# CC2753 register map
File version: 1.0
CPU: CM0+ r0p4, little endian, no MPU, no FPU, VTOR, 3 interrupt priority bits
Registers are 32-bit, read-write, reset 0x0 unless marked. A register's access mark holds for its fields unless they carry their own. Offsets are from the block's base; [hi:lo] are bit positions; {n}, {i} and the like mark numbered series; 'fields as' and 'values as' point back to an identical list.

## CKMD (part 2 of 2) — Clock Controller
Base 0x40001000
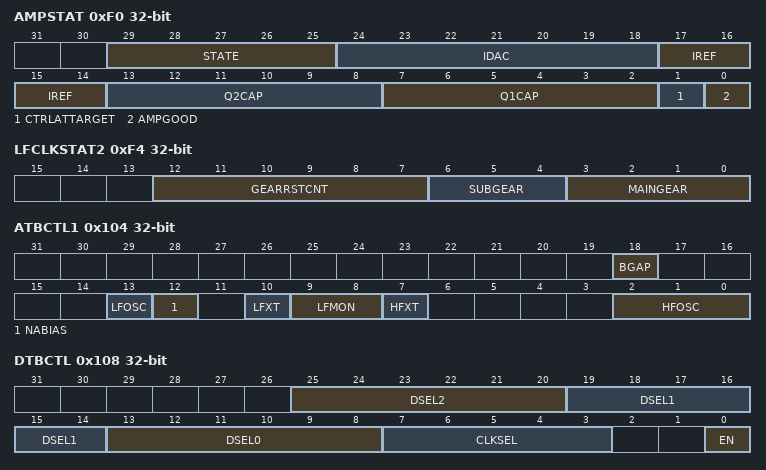
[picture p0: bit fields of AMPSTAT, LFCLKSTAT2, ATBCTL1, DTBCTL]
0xF0 AMPSTAT ro — HFXT Amplitude Compensation Status
  [29:25] STATE — Current AMPCOMP FSM state.
    15=SHUTDN1; 14=TXCOMODE; 13=SHUTDN0; 12=SETTLED; 10=TCXOWAIT; 7=RAMP1; 6=RAMP0; 5=UPDATEDN; 4=UPDATEUP; 3=INJECT; 2=INJWAIT; 1=LDOSTART; 0=IDLE
  [24:18] IDAC — Current IDAC control value.
  [17:14] IREF — Current IREF control value.
  [13:8] Q2CAP — Current Q2CAP control value.
  [7:2] Q1CAP — Current Q1CAP control value.
  [1] CTRLATTARGET — HFXT control values match target values. This applies to IREF, Q1CAP, Q2CAP values.
  [0] AMPGOOD — HFXT amplitude good
0xF4 LFCLKSTAT2 ro — Low-frequency clock status-2
  [12:7] GEARRSTCNT — Indicates the number of gear restarts. The counter is automatically cleared on the following events:- 1. Standby entry 2. Clearing RIS.LFGEARRSTRTLIM 3. Writing 0 to LFINCCTL2.GEARRSTRTLIM
  [6:4] SUBGEAR — The value of sub gear in LF filter. It counts from 0 to 7.
  [3:0] MAINGEAR — The value of main gear in LF filter. The main gear increments when the sub gear crosses 7.
0x100 ATBCTL0 — Analog test bus controls. This register is used in combination with ATBCTL1. For complete overview see [Block diagram] (https://confluence.itg.ti.com/display/LPRF/Hugin+-+AUXANATOP3+ATB+configuration#HuginAUXANATOP3ATBconfiguration-ATBdescription ) Ony the configurations mentioned in enumerations must be used. Other combinations might result in physical damage on the device. A write of 0x00 is recommended before changing to another connection configuration. All fields within this register are locked using the global-lock within SYS0.
  [23:0] SEL — Testmux selection ALWAYS write this signal to 0 (OFF), before selecting another configuration! Not following this might result in device damage.
    0x800000=LFDLYOPGATE (Gate output of LF delay block when set to 1); 0x400000=LFDLYINPGATE (Gate input clock to LF delay block when set to 1); 0x90000=BAWTESTCLK (BAW test clock connected to vr_atb_ckmanatop_clk); 0x50000=LFOSCTESTCLK (ull_ckm_lfosc_testclk connected to vr_atb_ckmanatop_clk); 0x30000=HFXTTESTCLK (ull_ckm_hfxt_testclk connected to vr_atb_ckmanatop_clk); 0x10000=HFOSCTESTCLK (ull_ckm_hfosc_testclk connected to vr_atb_ckmanatop_clk); 0x800=EXTCLKBUFPEAKDET (vr_atb_ckmextclkbuff_pd_mux_to_adc_o connected to vr_atb_ckmanatop_ana); 0x400=LFMONVTEST (vr_atb_lfmonitor_vtest connected to vr_atb_ckmanatop_ana); 0x200=BAWTEMP (BAW TEMPSENSE test output connected to vr_atb_ckmanatop_ana); 0x100=HFOSCOUT (vr_atb_hfosc_out connected to vr_atb_ckmanatop_ana); 128=NABIASITEST (vr_atb_nabias_itest_250n_dn connected to vr_atb_ckmanatop_ana); 64=ADCDACOUT (vr_atb_hfxtadc_dacout connected to vr_atb_ckmanatop_ana); 32=ADCCOMPIN (vr_atb_hfxtadc_compin connected to vr_atb_ckmanatop_ana); 16=ADCCOMPOUT (vr_atb_hfxtadc_compout connected to vr_atb_ckmanatop_ana); 8=BAWVBUF (BAW voltage buffer test output connected to vr_atb_ckmanatop_ana); 4=BAWCORE (BAW core test output connected to vr_atb_ckmanatop_ana); 2=VDDCKM (vr_atb_ckmldo_vddckm connected to vr_atb_ckmanatop_ana); 1=HFXTANA (vr_atb_hfxt_ana connected to vr_atb_ckmanatop_ana); 0=OFF (No signal connected to ATB. All outputs high impedance)
0x104 ATBCTL1 — Analog test bus controls This register is used in combination withATBCTL0. For complete overview see [Block diagram] (https://confluence.itg.ti.com/display/LPRF/Hugin+-+AUXANATOP3+ATB+configuration#HuginAUXANATOP3ATBconfiguration-ATBdescription ) All fields within this register are locked using the global-lock within SYS0.
  [18] BGAP — Control HFOSC voltage buffer test output signals Cannot be used if HFOSC is set to VREF or VINT. A write of 0x00 is recommended before changing to another connection configuration.
    1=VBUF (Enables HFOSC voltage buffer connection to ATB0.); 0=OFF (No output signal selected. Output is floating.)
  [13] LFOSC — Control LFOSC test output signals
    1=TESTCLK (LFOSC test clock); 0=OFF (No output signal selected. Output clock is grounded.)
  [12] NABIAS — Enable NABIAS test mode.
    1=ITEST (NABIAS Itest Enable.); 0=OFF (No output signal selected. Output signal is floating.)
  [10] LFXT — Control LFXT test output signals
    1=TESTCLK (LFXT test clock); 0=OFF (No output signal selected)
  [9:8] LFMON — Control LFMON test output signals
    3=TEST3 (LF monitor status signal); 2=TEST2 (Test signal 2 / in phase with inverted clock signal); 1=TEST1 (Test signal 1 / in phase with LF clock); 0=OFF (No output signal selected. Output signal is floating.)
  [7] HFXT — Enable HFXT test mode.
    1=IREF (HFXT CORE Iref connected to ATEST Bus and enable HFXT/BAW clock to test clock mux. Do not use this test feature if HFXT and BAW are on at the same time, this will damage the device); 0=OFF (No output signal selected. IREF output is floating, clocks are grounded.)
  [2:0] HFOSC — Control HFOSC test output signals VREF and VINT cannot be set at the same time, this might result in physical damage on the device. They also can't be used if BGAP is 0x1. TESTCLK can be used independantly all these enumerations. A write of 0x00 is recommended before changing to another connection configuration.
    4=TESTCLK (HFOSC test clock on ATB); 2=VINT (Enables internally generated supply connection to ATB); 1=VREF (Enables reference voltage connection to ATB); 0=OFF (No output signal selected. Voltage output is floating, clock output is grounded.)
0x108 DTBCTL — Digital test bus mux control
  [25:20] DSEL2 — Select data to output on DTB[15:11]
  [19:14] DSEL1 — Select data to output on DTB[10:6]
  [13:8] DSEL0 — Select data to output on DTB[5:1]
  [7:3] CLKSEL — Select clock to output on DTB[0]
  [0] EN — Enable DTB output
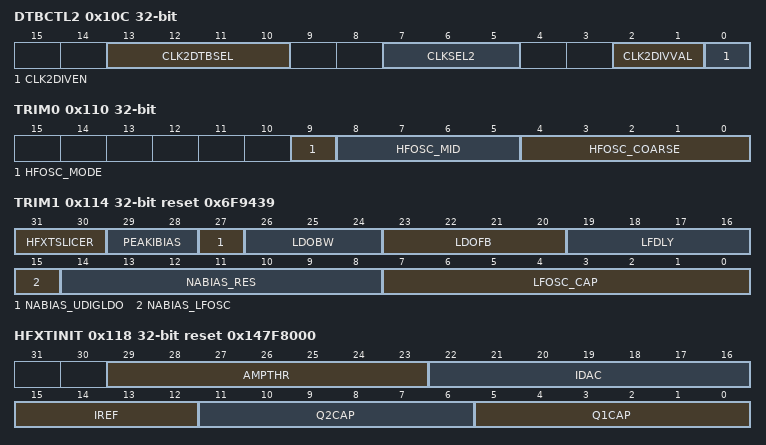
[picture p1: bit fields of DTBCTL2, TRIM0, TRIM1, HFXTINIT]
0x10C DTBCTL2 — Digital test bus mux control
  [13:10] CLK2DTBSEL — Select a DTB other than DTB0 to route the clock. Value of 0 indicates that clock 2 won't be sent to DTB.
  [7:5] CLKSEL2 — Select the clock that needs to be routed to a DTB other than DTB0
  [2:1] CLK2DIVVAL — These bits are used to configure the divider value.
    3=DIVBY16 (Divide by 16); 2=DIVBY8 (Divide by 8); 1=DIVBY4 (Divide by 4); 0=DIVBY2 (Divide by 2)
  [0] CLK2DIVEN — Enable divider on second clock path
    1=EN (Enable); 0=DIS (Disable)
0x110 TRIM0 — Production Trim Register 0 Note: This register contains the HFOSC coarse trims. Changing it might result in frequency overshoots. To prevent these from reaching the system, the clock is gated off for some periods after writing this register.
  [9] HFOSC_MODE — HFOSC mode trim. This field is locked using the global-lock within SYS0.
  [8:5] HFOSC_MID — HFOSC mid trim Binary coded. Default is 0x0. Never set to max code without a trim sweep. This field is locked using the global-lock within SYS0.
  [4:0] HFOSC_COARSE — HFOSC coarse trim. Binary coded. Default is 0x0. Never set to max code without a trim sweep. This field is locked using the global-lock within SYS0.
0x114 TRIM1 reset 0x6F9439 — Production Trim Register 1
  [31:30] HFXTSLICER — Bias current trim for HFXT slicer. 0x0: Minimum current 0x3: Maximum Current
  [29:28] PEAKIBIAS — IBIAS value for the HFXT peak detector 0x0: 16uA 0x1: 20uA 0x2: 24uA 0x3: 28uA"
  [27] NABIAS_UDIGLDO — Decrease uDIGLDO reference current by 25nA. 0x0: 50nA 0x1: 25nA This field is locked using the global-lock within SYS0.
  [26:24] LDOBW — CKMLDO gain-bandwidth trim 0x0: Minimum 0x7: Maximum
  [23:20] LDOFB — CKMLDO feedback trim. Trim of LDO output voltage 0x0: Minimum voltage 0x6: Trim target (~1.28V) 0xF: Maximum voltage
  [19:16] LFDLY — LF delay cell trim. Binary coded.
  [15] NABIAS_LFOSC — Increase LFOSC reference current by 25nA
  [14:8] NABIAS_RES — NABIAS resistor trim. Binary coded, with inverted 7th bit.
  [7:0] LFOSC_CAP — LFOSC res trim. Binary coded with inverted 8th bit. 0x7F max frequency 0x80 min frequency
0x118 HFXTINIT reset 0x147F8000 — Initial values for HFXT ramping
  [29:23] AMPTHR — Amplitude threshold during HFXT ramping
  [22:16] IDAC — Initial HFXT IDAC current
  [15:12] IREF — Initial HFXT IREF current
  [11:6] Q2CAP — Initial HFXT Q2 cap trim
    63=CAP63 (Nominal 25C = 1.10E-11 F Stong 25C = 1.00E-11 F Weak 25C = 1.19E-11 F); 62=CAP62 (Nominal 25C = 1.08E-11 F Stong 25C = 9.82E-12 F Weak 25C = 1.17E-11 F); 61=CAP61 (Nominal 25C = 1.06E-11 F Stong 25C = 9.64E-12 F Weak 25C = 1.15E-11 F); 60=CAP60 (Nominal 25C = 1.04E-11 F Stong 25C = 9.45E-12 F Weak 25C = 1.13E-11 F); 59=CAP59 (Nominal 25C = 1.02E-11 F Stong 25C = 9.26E-12 F Weak 25C = 1.11E-11 F); 58=CAP58 (Nominal 25C = 1.00E-11 F Stong 25C = 9.07E-12 F Weak 25C = 1.09E-11 F); 57=CAP57 (Nominal 25C = 9.84E-12 F Stong 25C = 8.89E-12 F Weak 25C = 1.07E-11 F); 56=CAP56 (Nominal 25C = 9.65E-12 F Stong 25C = 8.70E-12 F Weak 25C = 1.04E-11 F); 55=CAP55 (Nominal 25C = 9.46E-12 F Stong 25C = 8.51E-12 F Weak 25C = 1.02E-11 F); 54=CAP54 (Nominal 25C = 9.26E-12 F Stong 25C = 8.32E-12 F Weak 25C = 1.00E-11 F); 53=CAP53 (Nominal 25C = 9.07E-12 F Stong 25C = 8.13E-12 F Weak 25C = 9.81E-12 F); 52=CAP52 (Nominal 25C = 8.88E-12 F Stong 25C = 7.94E-12 F Weak 25C = 9.60E-12 F); 51=CAP51 (Nominal 25C = 8.69E-12 F Stong 25C = 7.76E-12 F Weak 25C = 9.39E-12 F); 50=CAP50 (Nominal 25C = 8.49E-12 F Stong 25C = 7.57E-12 F Weak 25C = 9.18E-12 F); 49=CAP49 (Nominal 25C = 8.30E-12 F Stong 25C = 7.38E-12 F Weak 25C = 8.96E-12 F); 48=CAP48 (Nominal 25C = 8.10E-12 F Stong 25C = 7.18E-12 F Weak 25C = 8.75E-12 F); 47=CAP47 (Nominal 25C = 8.10E-12 F Stong 25C = 7.18E-12 F Weak 25C = 8.75E-12 F); 46=CAP46 (Nominal 25C = 7.97E-12 F Stong 25C = 7.05E-12 F Weak 25C = 8.60E-12 F); 45=CAP45 (Nominal 25C = 7.83E-12 F Stong 25C = 6.91E-12 F Weak 25C = 8.44E-12 F); 44=CAP44 (Nominal 25C = 7.69E-12 F Stong 25C = 6.77E-12 F Weak 25C = 8.29E-12 F); 43=CAP43 (Nominal 25C = 7.55E-12 F Stong 25C = 6.63E-12 F Weak 25C = 8.13E-12 F); 42=CAP42 (Nominal 25C = 7.40E-12 F Stong 25C = 6.49E-12 F Weak 25C = 7.98E-12 F); 41=CAP41 (Nominal 25C = 7.26E-12 F Stong 25C = 6.35E-12 F Weak 25C = 7.82E-12 F); 40=CAP40 (Nominal 25C = 7.12E-12 F Stong 25C = 6.21E-12 F Weak 25C = 7.67E-12 F); 39=CAP39 (Nominal 25C = 6.98E-12 F Stong 25C = 6.06E-12 F Weak 25C = 7.51E-12 F); 38=CAP38 (Nominal 25C = 6.84E-12 F Stong 25C = 5.92E-12 F Weak 25C = 7.35E-12 F); 37=CAP37 (Nominal 25C = 6.69E-12 F Stong 25C = 5.78E-12 F Weak 25C = 7.20E-12 F); 36=CAP36 (Nominal 25C = 6.55E-12 F Stong 25C = 5.63E-12 F Weak 25C = 7.04E-12 F); 35=CAP35 (Nominal 25C = 6.41E-12 F Stong 25C = 5.49E-12 F Weak 25C = 6.88E-12 F); 34=CAP34 (Nominal 25C = 6.26E-12 F Stong 25C = 5.35E-12 F Weak 25C = 6.72E-12 F); 33=CAP33 (Nominal 25C = 6.12E-12 F Stong 25C = 5.20E-12 F Weak 25C = 6.56E-12 F); 32=CAP32 (Nominal 25C = 5.97E-12 F Stong 25C = 5.05E-12 F Weak 25C = 6.40E-12 F); 31=CAP31 (Nominal 25C = 5.72E-12 F Stong 25C = 4.79E-12 F Weak 25C = 6.12E-12 F); 30=CAP30 (Nominal 25C = 5.60E-12 F Stong 25C = 4.67E-12 F Weak 25C = 5.99E-12 F); 29=CAP29 (Nominal 25C = 5.49E-12 F Stong 25C = 4.56E-12 F Weak 25C = 5.87E-12 F); 28=CAP28 (Nominal 25C = 5.37E-12 F Stong 25C = 4.44E-12 F Weak 25C = 5.74E-12 F); 27=CAP27 (Nominal 25C = 5.26E-12 F Stong 25C = 4.32E-12 F Weak 25C = 5.61E-12 F); 26=CAP26 (Nominal 25C = 5.15E-12 F Stong 25C = 4.21E-12 F Weak 25C = 5.49E-12 F); 25=CAP25 (Nominal 25C = 5.03E-12 F Stong 25C = 4.09E-12 F Weak 25C = 5.36E-12 F); 24=CAP24 (Nominal 25C = 4.91E-12 F Stong 25C = 3.97E-12 F Weak 25C = 5.23E-12 F); 23=CAP23 (Nominal 25C = 4.80E-12 F Stong 25C = 3.85E-12 F Weak 25C = 5.10E-12 F); 22=CAP22 (Nominal 25C = 4.68E-12 F Stong 25C = 3.73E-12 F Weak 25C = 4.98E-12 F); 21=CAP21 (Nominal 25C = 4.57E-12 F Stong 25C = 3.60E-12 F Weak 25C = 4.85E-12 F); 20=CAP20 (Nominal 25C = 4.45E-12 F Stong 25C = 3.48E-12 F Weak 25C = 4.72E-12 F); 19=CAP19 (Nominal 25C = 4.33E-12 F Stong 25C = 3.36E-12 F Weak 25C = 4.59E-12 F); 18=CAP18 (Nominal 25C = 4.21E-12 F Stong 25C = 3.23E-12 F Weak 25C = 4.46E-12 F); 17=CAP17 (Nominal 25C = 4.09E-12 F Stong 25C = 3.11E-12 F Weak 25C = 4.33E-12 F); 16=CAP16 (Nominal 25C = 3.97E-12 F Stong 25C = 2.98E-12 F Weak 25C = 4.20E-12 F); 15=CAP15 (Nominal 25C = 3.97E-12 F Stong 25C = 2.98E-12 F Weak 25C = 4.20E-12 F); 14=CAP14 (Nominal 25C = 3.88E-12 F Stong 25C = 2.89E-12 F Weak 25C = 4.10E-12 F); 13=CAP13 (Nominal 25C = 3.79E-12 F Stong 25C = 2.79E-12 F Weak 25C = 4.00E-12 F); 12=CAP12 (Nominal 25C = 3.70E-12 F Stong 25C = 2.69E-12 F Weak 25C = 3.90E-12 F); 11=CAP11 (Nominal 25C = 3.61E-12 F Stong 25C = 2.59E-12 F Weak 25C = 3.80E-12 F); 10=CAP10 (Nominal 25C = 3.51E-12 F Stong 25C = 2.49E-12 F Weak 25C = 3.70E-12 F); 9=CAP9 (Nominal 25C = 3.42E-12 F Stong 25C = 2.39E-12 F Weak 25C = 3.60E-12 F); 8=CAP8 (Nominal 25C = 3.33E-12 F Stong 25C = 2.29E-12 F Weak 25C = 3.50E-12 F); 7=CAP7 (Nominal 25C = 3.23E-12 F Stong 25C = 2.19E-12 F Weak 25C = 3.40E-12 F); 6=CAP6 (Nominal 25C = 3.14E-12 F Stong 25C = 2.09E-12 F Weak 25C = 3.30E-12 F); 5=CAP5 (Nominal 25C = 3.04E-12 F Stong 25C = 1.99E-12 F Weak 25C = 3.19E-12 F); 4=CAP4 (Nominal 25C = 2.95E-12 F Stong 25C = 1.89E-12 F Weak 25C = 3.09E-12 F); 3=CAP3 (Nominal 25C = 2.85E-12 F Stong 25C = 1.79E-12 F Weak 25C = 2.99E-12 F); 2=CAP2 (Nominal 25C = 2.76E-12 F Stong 25C = 1.69E-12 F Weak 25C = 2.89E-12 F); 1=CAP1 (Nominal 25C = 2.66E-12 F Stong 25C = 1.60E-12 F Weak 25C = 2.79E-12 F); 0=CAP0 (Nominal 25C = 2.57E-12 F Stong 25C = 1.50E-12 F Weak 25C = 2.69E-12 F)
  [5:0] Q1CAP — Initial HFXT Q1 cap trim
    values as Q2CAP
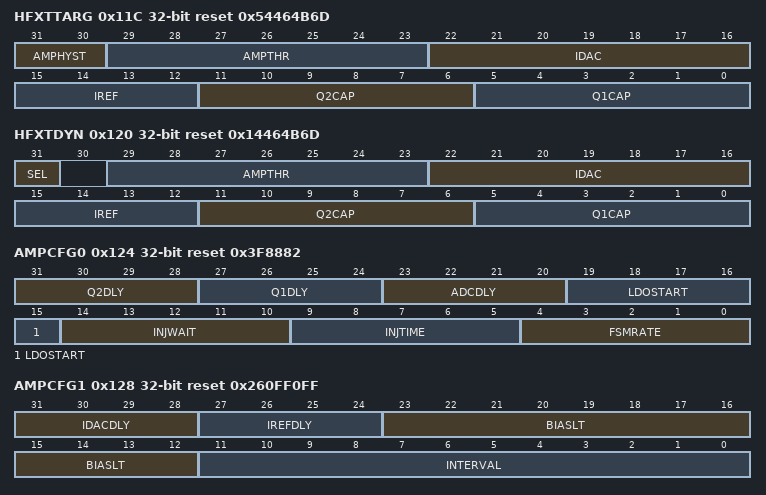
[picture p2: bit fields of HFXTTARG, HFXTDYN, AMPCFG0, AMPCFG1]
0x11C HFXTTARG reset 0x54464B6D — Target values for HFXT ramping
  [31:30] AMPHYST — ADC hysteresis used during IDAC updates. Every AMPCFG0.INTERVAL, IDAC will be regulated - up as long as ADC $lt; AMPTHR - down as long as ADC $gt; AMPTHR+AMPHYST
  [29:23] AMPTHR — Minimum HFXT amplitude
  [22:16] IDAC — Minimum IDAC current
  [15:12] IREF — Target HFXT IREF current
  [11:6] Q2CAP — Target HFXT Q2 cap trim
    values as HFXTINIT.Q2CAP
  [5:0] Q1CAP — Target HFXT Q1 cap trim
    values as HFXTINIT.Q2CAP
0x120 HFXTDYN reset 0x14464B6D — Alternative target values for HFXT configuration Software can change these values to dynamically transition the HFXT configuration while HFXT is running. Set SEL to select the alternative set of target values.
  [31] SEL — Select the dynamic configuration. Amplitude ramping will always happen using the values in HFXTINIT, and HFXTTARG. Afterwards, this bit can be used to select between HFXTTARG and HFXTDYN. Hardware will ensure a smooth transition of analog control signals.
    1=DYNAMIC (Select configuration in CKM.HFXTDYN0 and CKM.HFXTDYN1.); 0=TARGET (Select configuration in CKM.HFXTTARG0 and CKM.HFXTTARG1.)
  [29:23] AMPTHR — HFXT ADC amplitude, Control of comparator reference voltage (resistive DAC) 0x00: Minimum voltage 0x7F: Maximum voltage LSB ~ 5mV
  [22:16] IDAC — Minimum IDAC current. Binary coded 0x0: Min current 0x7f: Max current
  [15:12] IREF — Target HFXT IREF current. Thermometer Coded 0x0: Min current 0x8: Max current
  [11:6] Q2CAP — Target HFXT Q2 cap trim
    values as HFXTINIT.Q2CAP
  [5:0] Q1CAP — Target HFXT Q1 cap trim
    values as HFXTINIT.Q2CAP
0x124 AMPCFG0 reset 0x3F8882 — Amplitude Compensation Configuration 0
  [31:28] Q2DLY — Q2CAP change delay. Number of clock cycles to wait before changing Q2CAP by one step. Clock frequency defined in FSMRATE.
  [27:24] Q1DLY — Q1CAP change delay. Number of clock cycles to wait before changing Q1CAP by one step. Clock frequency defined in FSMRATE.
  [23:20] ADCDLY — ADC and PEAKDET startup time. Number of clock cycles to wait after enabling the PEAKDET and ADC before the first measurement. Clock frequency defined in FSMRATE.
  [19:15] LDOSTART — LDO startup time. Number of clock cycles to bypass the LDO resistors for faster startup. Clock frequency defined in FSMRATE.
  [14:10] INJWAIT — Inject HFOSC for faster HFXT startup. This value specifies the number of clock cycles to wait after injection is done. The clock speed is defined in FSMRATE.
  [9:5] INJTIME — Inject HFOSC for faster HFXT startup. This value specifies the number of clock cycles the injection is enabled. The clock speed is defined in FSMRATE. Set to 0 to disable injection.
  [4:0] FSMRATE — Update rate for the AMPCOMP update rate. Also affects the clock rate for the Amplitude ADC. The update rate is 6MHz / (FSMRATE+1).
    23=_250K (250 kHz); 11=_500K (500 kHz); 5=_1M (1 MHz); 2=_2M (2 MHz); 1=_3M (3 MHz); 0=_6M (6 MHz)
0x128 AMPCFG1 reset 0x260FF0FF — Amplitude Compensation Configuration 1
  [31:28] IDACDLY — IDAC change delay. Time to wait before changing IDAC by one step. This time needs to be long enough for the crystal to settle. The number of clock cycles to wait is IDACDLY$lt;$lt;4 + 15. Clock frequency defined in AMPCFG0.FSMRATE.
  [27:24] IREFDLY — IREF change delay. Number of clock cycles to wait before changing IREF by one step. Clock frequency defined in AMPCFG0.FSMRATE.
  [23:12] BIASLT — Lifetime of the amplitude ADC bias value. This value specifies the number of adjustment intervals, until the ADC bias value has to be measured again. Set to 0 to disable automatic bias measurements.
  [11:0] INTERVAL — Interval for amplitude adjustments. Set to 0 to disable periodic adjustments. This value specifies the number of clock cycles between adjustments. The clock speed is defined in [CKM.AMPCFG0.FSMRATE].
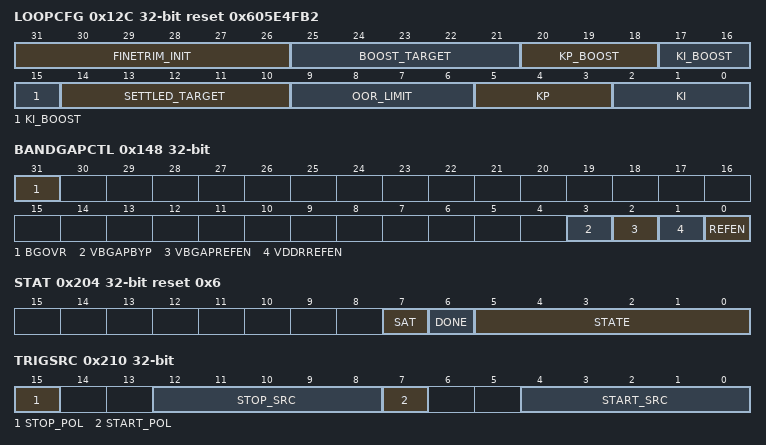
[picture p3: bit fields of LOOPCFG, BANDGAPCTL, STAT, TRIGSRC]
0x12C LOOPCFG reset 0x605E4FB2 — Configuration Register for the Tracking Loop. Writing to this MMR will override the filter output to FINETRIM_INIT.
  [31:26] FINETRIM_INIT — Initial value for the resistor fine trim
  [25:21] BOOST_TARGET — Error-updates for 4xBOOST_TARGET times using KI_BOOST/KP_BOOST, before using KI/KP. Note: If boost is used for long duration using large values of KI_BOOST $amp; KP_BOOST, the oscillator frequency can reach well above the max frequence limit of the design, causing unexpected behaviour.
  [20:18] KP_BOOST — Proportional loop coefficient during BOOST
  [17:15] KI_BOOST — Integral loop coefficient during BOOST
  [14:10] SETTLED_TARGET — Number of HFOSC tracking loop updates before HFOSC is considered "settled". The tracking loop updates at a rough frequency of (2*Reference frequency/256). If the reference frequency is 48MHz, the loop update frequency comes out to be 375Khz. Internally the MMR is multiplied by 4
  [9:6] OOR_LIMIT — Out-of-range threshold. OOR_LIMIT is compared with absolute value of 5 MSB bits of loop filter error.
  [5:3] KP — Proportional loop coefficient
  [2:0] KI — Integral loop coefficient
0x130 LOOPCFG1 — Configuration Register for HFOSC
  [25] SETTLEIRQ — Configuration to enable the interrupt when the HFOSC tracking loop has settled. The interrupt will be based on LOOPCFG.SETTLED_TARGET.
    1=ENABLE (Enable the interrupt to indicate that HFOSC tracking loop has settled.); 0=DISABLE (Disable the interrupt to indicate that HFOSC tracking loop has settled.)
0x148 BANDGAPCTL — Configuration Register for the HFOSC bandgap circuit
  [31] BGOVR — Software override for bandgap control signals. This field is locked using the global-lock within SYS0.
  [3] VBGAPBYP — Bypass of low-pass filter at input of voltage buffer of HFOSC. 0x0: Filter is not bypassed (after startup and settling of all nodes) 0x1: Filter is bypassed (during startup) This MMR is used only when BGOVR is set.
  [2] VBGAPREFEN — Configuration of reference voltage of HFOSC 0x0: BGAP reference is not used as reference 0x1: BGAP reference is used as a reference This MMR is used only when BGOVR is set.
  [1] VDDRREFEN — Configuration of reference voltage of HFOSC 0x0 : VDDR is not used as reference 0x 1: VDDR is used as a reference This MMR is used only when BGOVR is set.
  [0] REFEN — Enable voltage buffer for reference voltage of HFOSC 0x0: Disabled 0x1: Enabled This MMR is used only when BGOVR is set.
0x150 AFCLKSEL — Audio clock selection
  [2:0] SRC — Select audio frequency clock source Software should make sure that proper clock is selected before enabling the audio IP.
    4=CLKEXT (External clock); 3=CLKREF (48MHz reference clock (HFXT)); 2=CLKHF (96MHz CLKHF); 1=DIS2 (Clock Disabled); 0=DIS (Clock disabled)
0x198 TCXOCTL reset 0xC8 — TCXO control
  [11:0] WAITDLY — Time period to wait for after enabling the external TCXO. Delay = (2^5) * WAITDLY * (([CKM.AMPCFG0.FSMRATE]+1)/6MHz)
0x200 CTL — Control
  [1:0] CMD wo — TDC commands.
    3=ABORT (Force TDC state machine back to IDLE state. Never write this command while [TDC.STAT.STATE] equals CLR_CNT or WAIT_CLR_CNT_DONE.); 2=RUN (Asynchronous counter start. The counter starts to count when the start event is high. To achieve precise edge-to-edge measurements you must ensure that the start event is low for at least 420 ns after you write this command.); 1=RUN_SYNC_START (Synchronous counter start. The counter looks for the opposite edge of the selected start event before it starts to count when the selected edge occurs. This guarantees an edge-triggered start and is recommended for frequency measurements.); 0=CLR_RESULT (Clear [TDC.STAT.SAT], [TDC.STAT.DONE], and [TDC.RESULT.VALUE]. This is not needed as prerequisite for a measurement. Reliable clear is only guaranteed from IDLE state.)
0x204 STAT ro reset 0x6 — Status
  [7] SAT — TDC measurement saturation flag. 0: Conversion has not saturated. 1: Conversion stopped due to saturation. This field is cleared when a new measurement is started or when CLR_RESULT is written to [TDC.CTL.CMD].
  [6] DONE — TDC measurement complete flag. 0: TDC measurement has not yet completed. 1: TDC measurement has completed. This field clears when a new TDC measurement starts or when you write CLR_RESULT to [TDC.CTL.CMD].
  [5:0] STATE — TDC state machine status.
    46=FORCE_STOP (Current state is TDC_FORCESTOP. You wrote ABORT to [TDC.CTL.CMD] to abort the TDC measurement.); 30=START_FALL (Current state is TDC_WAIT_STARTFALL. The fast-counter circuit waits for a falling edge on the start event.); 22=WAIT_CLR_CNT_DONE (Current state is TDC_STATE_WAIT_CLRCNT_DONE. The state machine waits for fast-counter circuit to finish reset.); 15=POR (Current state is TDC_STATE_POR. This is the reset state.); 14=GET_RESULT (Current state is TDC_STATE_GETRESULTS. The state machine copies the counter value from the fast-counter circuit.); 12=WAIT_STOP_CNTDWN (Current state is TDC_STATE_WAIT_STOPCNTDOWN. The fast-counter circuit looks for the stop condition. It will ignore a number of stop events configured in [TDC.TRIGCNTLOAD.CNT].); 8=WAIT_STOP (Current state is TDC_STATE_WAIT_STOP. The state machine waits for the fast-counter circuit to stop.); 7=CLR_CNT (Current state is TDC_STATE_CLRCNT. The fast-counter circuit is reset.); 6=IDLE (Current state is TDC_STATE_IDLE. This is the default state after reset and abortion. State will change when you write [TDC.CTL.CMD] to either RUN_SYNC_START or RUN.); 4=WAIT_START_STOP_CNT_EN (Current state is TDC_STATE_WAIT_STARTSTOPCNTEN. The fast-counter circuit looks for the start condition. The state machine waits for the fast-counter to increment.); 0=WAIT_START (Current state is TDC_STATE_WAIT_START. The fast-counter circuit looks for the start condition. The state machine waits for the fast-counter to increment.)
0x208 RESULT ro reset 0x2 — Result Result of last TDC conversion.
  [31:0] VALUE — TDC conversion result. The result of the TDC conversion is given in number of clock edges of the clock source selected in [IPSPECIFIC.CKM.TDCCLKSEL.REFCLK]. Both rising and falling edges are counted. Note that [TDC.SATCFG.LIMIT] is given in periods, while VALUE is given in edges (periods*2). If TDC counter saturates, VALUE is slightly higher than [TDC.SATCFG.LIMIT]*2, as it takes a non-zero time to stop the measurement. Hence, the maximum value of this field becomes slightly higher than 2^31 (2^30 periods*2) if you configure [TDC.SATCFG.LIMIT] to R30.
0x20C SATCFG — Saturation Configuration
  [4:0] LIMIT — Saturation limit. The flag [TDC.STAT.SAT] is set when the TDC counter saturates. Note that this value is given in periods, while [TDC.RESULT.VALUE] is given in edges (periods*2). Values not enumerated are not supported
    {v}=R{v+9} (TDC conversion saturates and stops after 2^{v+9} periods.) (v=3..21); 0=NONE (No saturation. An additional timer should be used to know if [TDC.RESULT.VALUE] rolled over.)
0x210 TRIGSRC — Trigger Source Select source and polarity for TDC start and stop events. See the Technical Reference Manual for event timing requirements.
  [15] STOP_POL — Polarity of stop source. Change only while [TDC.STAT.STATE] is IDLE.
    1=LOW (TDC conversion stops when low level is detected.); 0=HIGH (TDC conversion stops when high level is detected.)
  [12:8] STOP_SRC — Select stop source from the asynchronous AUX event bus. Change only while [TDC.STAT.STATE] is IDLE.
    31=TDC_PRE (Select TDC Prescaler event which is generated by configuration of TDC.PRECTL.); {v}=DTB{v-5} (Digital testbus bit {v-5}) (v=5..20); 4=GPI (General purpose input signal); 3=LFCLK_DLY (Delayed version of selected LFCLK); 1=LFOSC (Low frequency on-chip oscillator); 0=LFTICK (LFTICK signal going to the RTC)
  [7] START_POL — Polarity of start source. Change only while [TDC.STAT.STATE] is IDLE.
    1=LOW (TDC conversion starts when low level is detected.); 0=HIGH (TDC conversion starts when high level is detected.)
  [4:0] START_SRC — Select start source from the asynchronous AUX event bus. Change only while [TDC.STAT.STATE] is IDLE.
    values as STOP_SRC
0x214 TRIGCNT — Trigger Counter Stop-counter control and status.
  [15:0] CNT — Number of stop events to ignore when [TDC.TRIGCNTCFG.EN] is 1. Read CNT to get the remaining number of stop events to ignore during a TDC measurement. Write CNT to update the remaining number of stop events to ignore during a TDC measurement. The TDC measurement ignores updates of CNT if there are no more stop events left to ignore. When [TDC.TRIGCNTCFG.EN] is 1, [TDC.TRIGCNTLOAD.CNT] is loaded into CNT at the start of the measurement.
0x218 TRIGCNTLOAD — Trigger Counter Load Stop-counter load.
  [15:0] CNT — Number of stop events to ignore when [TDC.TRIGCNTCFG.EN] is 1. To measure frequency of an event source: - Set start event equal to stop event. - Set CNT to number of periods to measure. Both 0 and 1 values measures a single event source period. To measure pulse width of an event source: - Set start event source equal to stop event source. - Select different polarity for start and stop event. - Set CNT to 0. To measure time from the start event to the Nth stop event when N $gt; 1: - Select different start and stop event source. - Set CNT to (N-1). See the Technical Reference Manual for event timing requirements. When [TDC.TRIGCNTCFG.EN] is 1, CNT is loaded into [TDC.TRIGCNT.CNT] at the start of the measurement.
0x21C TRIGCNTCFG — Trigger Counter Configuration Stop-counter configuration.
  [0] EN — Enable stop-counter. 0: Disable stop-counter. 1: Enable stop-counter. Change only while [TDC.STAT.STATE] is IDLE.
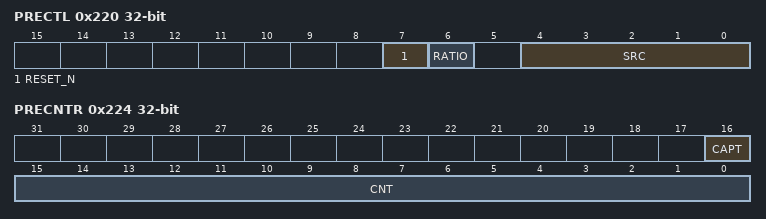
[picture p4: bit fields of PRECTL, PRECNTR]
0x220 PRECTL — Prescaler Control The prescaler can be used to count events that are faster than the bus rate. It can be used to: - count pulses on a specified event from the asynchronous event bus. - prescale a specified event from the asynchronous event bus. To use the prescaler output as an event source in TDC measurements you must set both TRIGSRC.START_SRC and TRIGSRC.STOP_SRC to TDC_PRE. It is recommended to use the prescaler when the signal frequency to measure exceeds 1/10th of the bus rate.
  [7] RESET_N — Prescaler reset. 0: Reset prescaler. 1: Release reset of prescaler. AUX_TDC_PRE event becomes 0 when you reset the prescaler.
  [6] RATIO — Prescaler ratio. This controls how often the TDC_PRE event is generated by the prescaler.
    1=DIV64 (Prescaler divides input by 64. AUX_TDC_PRE event has a rising edge for every 64 rising edges of the input. AUX_TDC_PRE event toggles on every 32nd rising edge of the input.); 0=DIV16 (Prescaler divides input by 16. AUX_TDC_PRE event has a rising edge for every 16 rising edges of the input. AUX_TDC_PRE event toggles on every 8th rising edge of the input.)
  [4:0] SRC — Prescaler event source. Select an event from the asynchronous AUX event bus to connect to the prescaler input. Configure only while RESET_N is 0.
    22=HFXT (High frequency crystal oscillator); 21=HFOSC (High frequency on-chip oscillator); {v}=DTB{v-5} (Digital testbus bit {v-5}) (v=5..20); 4=GPI (General purpose input signal); 3=LFCLK_DLY (Delayed version of selected LFCLK); 1=LFOSC (Low frequency on-chip oscillator); 0=LFTICK (LFTICK signal going to the RTC)
0x224 PRECNTR — Prescaler Counter
  [16] CAPT wo — Prescaler counter capture strobe. Write a 1 to CAPT to capture the value of the 16-bit prescaler counter into CNT. Read CNT to get the captured value.
  [15:0] CNT ro — Prescaler counter value. Write a 1 to CAPT to capture the value of the 16-bit prescaler counter into CNT. Read CNT to get the captured value. The read value gets 1 LSB uncertainty if the event source level rises when you release the reset. The read value gets 1 LSB uncertainty if the event source level rises when you capture the prescaler counter. Please note the following: - The prescaler counter is reset to 3 by [TDC.PRECTL.RESET_N]. - The captured value is 3 when the number of rising edges on prescaler input is less than 3. Otherwise, captured value equals number of event pulses.
0x300 CNT — WDT counter value register
  [31:0] VAL — Counter value. A write to this field immediately starts (or restarts) the counter. It will count down from the written value. If the counter reaches 0, a reset will be generated. A write value of 0 immediately generates a reset. This field is only writable if not locked. See LOCK register. Writing this field will automatically activate the lock. A read returns the current value of the counter.
0x304 TEST — WDT test mode register
  [0] STALLEN — WDT stall enable This field is only writable if not locked. See LOCK register.
    1=EN (ENABLE WDT stops counting while the CPU is stopped by a debugger.); 0=DIS (DISABLE WDT continues counting while the CPU is stopped by a debugger.)
0x308 LOCK reset 0x1 — WDT lock register
  [31:0] STAT — A write with value 0x1ACCE551 unlocks the watchdog registers for write access. A write with any other value locks the watchdog registers for write access. Writing the CNT register will also lock the watchdog registers. A read of this field returns the state of the lock (0=unlocked, 1=locked).
